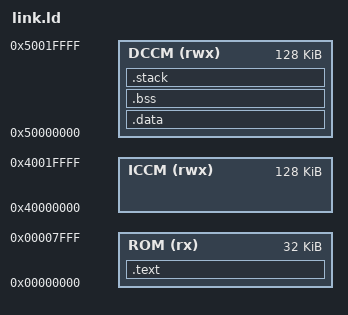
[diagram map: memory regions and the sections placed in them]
/*++

Licensed under the Apache-2.0 license.

File Name:

    main.rs

Abstract:

    File contains linker script for bare-metal RISCV program

--*/


ENTRY(_start)
OUTPUT_ARCH( "riscv" )

MEMORY
{
  ROM   (rx) : ORIGIN = 0x00000000, LENGTH = 32K
  ICCM (rwx) : ORIGIN = 0x40000000, LENGTH = 128K
  DCCM (rwx) : ORIGIN = 0x50000000, LENGTH = 128K
}

STACK_SIZE = 0x1000;

SECTIONS
{
    .text :
    {
        *(.text.init )
        *(.text*)
        *(.rodata*)
    } > ROM

    ROM_DATA = .;

    .data : AT(ROM_DATA)
    {
        . = ALIGN(4);
        *(.data*);
        *(.sdata*);
        KEEP(*(.eh_frame))
        . = ALIGN(4);
        PROVIDE( GLOBAL_POINTER = . + 0x800 );
        . = ALIGN(4);
    } > DCCM

    .bss (NOLOAD) :
    {
        . = ALIGN(4);
        *(.bss*)
        *(.sbss*)
        *(COMMON)
        . = ALIGN(4);
    } > DCCM

    .stack (NOLOAD):
    {
        . = ALIGN(4);
        . = . + STACK_SIZE;
        . = ALIGN(4);
        PROVIDE(STACK_START = . );
    } > DCCM

    _end = . ;
}

BSS_START = ADDR(.bss);
BSS_END = BSS_START + SIZEOF(.bss);
DATA_START = ADDR(.data);
DATA_END = DATA_START + SIZEOF(.data);
ROM_DATA_START = LOADADDR(.data);
